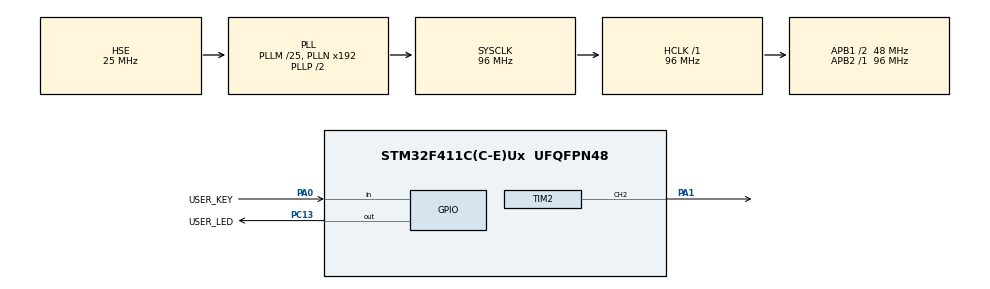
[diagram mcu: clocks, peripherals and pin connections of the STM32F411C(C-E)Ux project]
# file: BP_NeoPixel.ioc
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Mcu.Family=STM32F4
Mcu.Name=STM32F411C(C-E)Ux
Mcu.Package=UFQFPN48
NVIC.PriorityGroup=NVIC_PRIORITYGROUP_4
PA0-WKUP.GPIO_Label=USER_KEY
PA0-WKUP.GPIO_PuPd=GPIO_PULLUP
PA0-WKUP.Signal=GPIO_Input
PA1.Signal=S_TIM2_CH2
PA13.Mode=Serial_Wire
PA13.Signal=SYS_JTMS-SWDIO
PA14.Mode=Serial_Wire
PA14.Signal=SYS_JTCK-SWCLK
PC13-ANTI_TAMP.GPIO_Label=USER_LED
PC13-ANTI_TAMP.GPIO_ModeDefaultOutputPP=GPIO_MODE_OUTPUT_PP
PC13-ANTI_TAMP.GPIO_PuPd=GPIO_NOPULL
PC13-ANTI_TAMP.GPIO_Speed=GPIO_SPEED_FREQ_LOW
PC13-ANTI_TAMP.PinState=GPIO_PIN_RESET
PC13-ANTI_TAMP.Signal=GPIO_Output
PC14-OSC32_IN.Mode=LSE-External-Oscillator
PC14-OSC32_IN.Signal=RCC_OSC32_IN
PC15-OSC32_OUT.Mode=LSE-External-Oscillator
PC15-OSC32_OUT.Signal=RCC_OSC32_OUT
PH0\ -\ OSC_IN.Mode=HSE-External-Oscillator
PH0\ -\ OSC_IN.Signal=RCC_OSC_IN
PH1\ -\ OSC_OUT.Mode=HSE-External-Oscillator
PH1\ -\ OSC_OUT.Signal=RCC_OSC_OUT
ProjectManager.HeapSize=0x200
ProjectManager.StackSize=0x400
ProjectManager.TargetToolchain=STM32CubeIDE
RCC.48MHZClocksFreq_Value=48000000
RCC.AHBFreq_Value=96000000
RCC.APB1CLKDivider=RCC_HCLK_DIV2
RCC.APB1Freq_Value=48000000
RCC.APB1TimFreq_Value=96000000
RCC.APB2Freq_Value=96000000
RCC.APB2TimFreq_Value=96000000
RCC.CortexFreq_Value=96000000
RCC.HCLKFreq_Value=96000000
RCC.HSE_VALUE=25000000
RCC.HSI_VALUE=16000000
RCC.PLLM=25
RCC.PLLSourceVirtual=RCC_PLLSOURCE_HSE
RCC.RCC_RTC_Clock_Source=RCC_RTCCLKSOURCE_LSE
RCC.RCC_RTC_Clock_SourceVirtual=RCC_RTCCLKSOURCE_LSE
RCC.SYSCLKFreq_VALUE=96000000
RCC.SYSCLKSource=RCC_SYSCLKSOURCE_PLLCLK
RCC.VCOOutputFreq_Value=192000000
SH.S_TIM2_CH2.0=TIM2_CH2,PWM Generation2 CH2
TIM2.Channel-PWM\ Generation2\ CH2=TIM_CHANNEL_2
TIM2.OCFastMode_PWM-PWM\ Generation2\ CH2=TIM_OCFAST_DISABLE
TIM2.Period=96000000
TIM2.Pulse-PWM\ Generation2\ CH2=48000000
VP_TIM2_VS_ClockSourceINT.Mode=Internal
board=custom

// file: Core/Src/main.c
/* USER CODE BEGIN Header */
/**
  ******************************************************************************
  * @file           : main.c
  * @brief          : Main program body
  ******************************************************************************
  * @attention
  *
  * <h2><center>&copy; Copyright (c) 2020 STMicroelectronics.
  * All rights reserved.</center></h2>
  *
  * This software component is licensed by ST under BSD 3-Clause license,
  * the "License"; You may not use this file except in compliance with the
  * License. You may obtain a copy of the License at:
  *                        opensource.org/licenses/BSD-3-Clause
  *
  ******************************************************************************
  */
/* USER CODE END Header */
#include "main.h"

/* USER CODE BEGIN PD */

#define WS_LED_COUNT 30
#define WS_BYTES_PER_LED 3
#define WS_BITS_PER_LED  (WS_BYTES_PER_LED * 8)

#define SUCCESS 0
#define ERR_INDEX_OUT_OF_RANGE 1;
#define ERR_UPDATING 2;

/* USER CODE END PD */

TIM_HandleTypeDef htim2;

/* USER CODE BEGIN PV */
static uint8_t led_colors[WS_BYTES_PER_LED * WS_LED_COUNT]; // array to hold the LED RGB Values
static uint32_t pwm_ccr_values[2 * WS_BITS_PER_LED];  //one 32bit PWM CCR value per RGB bit, and we need 2 sets.
static uint8_t          is_reset_pulse;     /*!< Status if we are sending reset pulse or led data */
static volatile uint8_t is_updating;        /*!< Is updating in progress? */
static uint32_t         current_led;        /*!< Current LED number we are sending */

/* USER CODE END PV */

void SystemClock_Config(void);
static void MX_GPIO_Init(void);
static void MX_TIM2_Init(void);
/* USER CODE BEGIN PFP */

uint8_t ws_set_color(uint32_t index, uint8_t r, uint8_t g, uint8_t b);
uint8_t ws_set_color_rgb(uint32_t index, uint32_t rgb);
uint8_t ws_set_color_all(uint8_t r, uint8_t g, uint8_t b);
uint8_t ws_set_color_all_rgb(uint32_t rgb);

uint8_t led_update(uint8_t block);
uint8_t led_is_update_finished(void);
uint8_t led_start_reset_pulse(uint8_t num);

/* USER CODE END PFP */

/* USER CODE BEGIN 0 */

uint8_t ws_set_color(uint32_t index, uint8_t r, uint8_t g, uint8_t b)
{
	if (index > WS_LED_COUNT){
		return ERR_INDEX_OUT_OF_RANGE;
	}

	uint32_t offset = index * 3;
	led_colors[offset] = r;
	led_colors[offset+1] = g;
	led_colors[offset+ 2] = b;
	return SUCCESS;
}

uint8_t ws_set_color_rgb(uint32_t index, uint32_t rgb)
{
	if (index > WS_LED_COUNT){
		return ERR_INDEX_OUT_OF_RANGE;
	}

	uint32_t offset = index * 3;
	uint8_t* color = (uint8_t*)&rgb;
	led_colors[offset] = color[0];
	led_colors[offset+1] = color[1];
	led_colors[offset+ 2] = color[2];

	return SUCCESS;
}

uint8_t ws_set_color_all(uint8_t r, uint8_t g, uint8_t b)
{
	for (uint32_t index = 0; index < WS_LED_COUNT * 3; index += 3)
	{
		led_colors[index] = r;
		led_colors[index + 1] = g;
		led_colors[index + 2] = b;
	}
	return SUCCESS;
}

uint8_t ws_set_color_all_rgb(uint32_t rgb)
{
	uint8_t* color = (uint8_t*) &rgb;
	for (uint32_t index = 0; index < WS_LED_COUNT * 3; index += 3)
	{
		led_colors[index] = color[0];
		led_colors[index + 1] = color[1];
		led_colors[index + 2] = color[2];
	}

	return SUCCESS;
}

uint8_t led_update(uint8_t block)
{
	if (is_updating){
		return ERR_UPDATING;
	}

	is_updating = 1;

	led_start_reset_pulse(1);
	if(block){
		while(!led_is_update_finished());
	}

	return SUCCESS;
}

uint8_t led_is_update_finished(void)
{
	return !is_updating;                        /* Return updating flag status */
}

uint8_t led_start_reset_pulse(uint8_t num){
	is_reset_pulse = num;

	memset(pwm_ccr_values, 0 , sizeof(pwm_ccr_values)); // set all bytes to zero

	if (num == 1){
		pwm_ccr_values[0] = htim2.Instance->ARR / 2;
	}

}

/* USER CODE END 0 */

int main(void)
{

  /* MCU Configuration--------------------------------------------------------*/

  /* Reset of all peripherals, Initializes the Flash interface and the Systick. */
  HAL_Init();

  /* Configure the system clock */
  SystemClock_Config();

  /* Initialize all configured peripherals */
  MX_GPIO_Init();
  MX_TIM2_Init();
  /* USER CODE BEGIN 2 */

  //HAL_TIM_PWM_Start(&htim2, TIM_CHANNEL_2);

  /* USER CODE END 2 */

  /* Infinite loop */
  /* USER CODE BEGIN WHILE */
  while (1)
  {
	  GPIO_PinState state = HAL_GPIO_ReadPin(USER_KEY_GPIO_Port, USER_KEY_Pin);
	  HAL_GPIO_WritePin(USER_LED_GPIO_Port, USER_LED_Pin, state);

	  if (state == GPIO_PIN_RESET){
		  //htim2.Instance->CCR2 = (htim2.Instance->ARR / 2);
		  HAL_TIM_PWM_Start(&htim2, TIM_CHANNEL_2);
	  }
	  else{
		  //htim2.Instance->CCR2 = (htim2.Instance->ARR / 4);
		  HAL_TIM_PWM_Stop(&htim2, TIM_CHANNEL_2);
	  }

	  HAL_Delay(100);
    /* USER CODE END WHILE */

  }
}

void SystemClock_Config(void)
{
  RCC_OscInitTypeDef RCC_OscInitStruct = {0};
  RCC_ClkInitTypeDef RCC_ClkInitStruct = {0};

  /** Configure the main internal regulator output voltage
  */
  __HAL_RCC_PWR_CLK_ENABLE();
  __HAL_PWR_VOLTAGESCALING_CONFIG(PWR_REGULATOR_VOLTAGE_SCALE1);
  /** Initializes the RCC Oscillators according to the specified parameters
  * in the RCC_OscInitTypeDef structure.
  */
  RCC_OscInitStruct.OscillatorType = RCC_OSCILLATORTYPE_HSE;
  RCC_OscInitStruct.HSEState = RCC_HSE_ON;
  RCC_OscInitStruct.PLL.PLLState = RCC_PLL_ON;
  RCC_OscInitStruct.PLL.PLLSource = RCC_PLLSOURCE_HSE;
  RCC_OscInitStruct.PLL.PLLM = 25;
  RCC_OscInitStruct.PLL.PLLN = 192;
  RCC_OscInitStruct.PLL.PLLP = RCC_PLLP_DIV2;
  RCC_OscInitStruct.PLL.PLLQ = 4;
  if (HAL_RCC_OscConfig(&RCC_OscInitStruct) != HAL_OK)
  {
    Error_Handler();
  }
  /** Initializes the CPU, AHB and APB buses clocks
  */
  RCC_ClkInitStruct.ClockType = RCC_CLOCKTYPE_HCLK|RCC_CLOCKTYPE_SYSCLK
                              |RCC_CLOCKTYPE_PCLK1|RCC_CLOCKTYPE_PCLK2;
  RCC_ClkInitStruct.SYSCLKSource = RCC_SYSCLKSOURCE_PLLCLK;
  RCC_ClkInitStruct.AHBCLKDivider = RCC_SYSCLK_DIV1;
  RCC_ClkInitStruct.APB1CLKDivider = RCC_HCLK_DIV2;
  RCC_ClkInitStruct.APB2CLKDivider = RCC_HCLK_DIV1;

  if (HAL_RCC_ClockConfig(&RCC_ClkInitStruct, FLASH_LATENCY_3) != HAL_OK)
  {
    Error_Handler();
  }
}

static void MX_TIM2_Init(void)
{

  TIM_ClockConfigTypeDef sClockSourceConfig = {0};
  TIM_MasterConfigTypeDef sMasterConfig = {0};
  TIM_OC_InitTypeDef sConfigOC = {0};

  htim2.Instance = TIM2;
  htim2.Init.Prescaler = 0;
  htim2.Init.CounterMode = TIM_COUNTERMODE_UP;
  htim2.Init.Period = 96000000;
  htim2.Init.ClockDivision = TIM_CLOCKDIVISION_DIV1;
  htim2.Init.AutoReloadPreload = TIM_AUTORELOAD_PRELOAD_DISABLE;
  if (HAL_TIM_Base_Init(&htim2) != HAL_OK)
  {
    Error_Handler();
  }
  sClockSourceConfig.ClockSource = TIM_CLOCKSOURCE_INTERNAL;
  if (HAL_TIM_ConfigClockSource(&htim2, &sClockSourceConfig) != HAL_OK)
  {
    Error_Handler();
  }
  if (HAL_TIM_PWM_Init(&htim2) != HAL_OK)
  {
    Error_Handler();
  }
  sMasterConfig.MasterOutputTrigger = TIM_TRGO_RESET;
  sMasterConfig.MasterSlaveMode = TIM_MASTERSLAVEMODE_DISABLE;
  if (HAL_TIMEx_MasterConfigSynchronization(&htim2, &sMasterConfig) != HAL_OK)
  {
    Error_Handler();
  }
  sConfigOC.OCMode = TIM_OCMODE_PWM1;
  sConfigOC.Pulse = 48000000;
  sConfigOC.OCPolarity = TIM_OCPOLARITY_HIGH;
  sConfigOC.OCFastMode = TIM_OCFAST_DISABLE;
  if (HAL_TIM_PWM_ConfigChannel(&htim2, &sConfigOC, TIM_CHANNEL_2) != HAL_OK)
  {
    Error_Handler();
  }
  HAL_TIM_MspPostInit(&htim2);

}

static void MX_GPIO_Init(void)
{
  GPIO_InitTypeDef GPIO_InitStruct = {0};

  /* GPIO Ports Clock Enable */
  __HAL_RCC_GPIOC_CLK_ENABLE();
  __HAL_RCC_GPIOH_CLK_ENABLE();
  __HAL_RCC_GPIOA_CLK_ENABLE();

  /*Configure GPIO pin Output Level */
  HAL_GPIO_WritePin(USER_LED_GPIO_Port, USER_LED_Pin, GPIO_PIN_RESET);

  /*Configure GPIO pin : USER_LED_Pin */
  GPIO_InitStruct.Pin = USER_LED_Pin;
  GPIO_InitStruct.Mode = GPIO_MODE_OUTPUT_PP;
  GPIO_InitStruct.Pull = GPIO_NOPULL;
  GPIO_InitStruct.Speed = GPIO_SPEED_FREQ_LOW;
  HAL_GPIO_Init(USER_LED_GPIO_Port, &GPIO_InitStruct);

  /*Configure GPIO pin : USER_KEY_Pin */
  GPIO_InitStruct.Pin = USER_KEY_Pin;
  GPIO_InitStruct.Mode = GPIO_MODE_INPUT;
  GPIO_InitStruct.Pull = GPIO_PULLUP;
  HAL_GPIO_Init(USER_KEY_GPIO_Port, &GPIO_InitStruct);

}

void Error_Handler(void)
{
}

/************************ (C) COPYRIGHT STMicroelectronics *****END OF FILE****/
